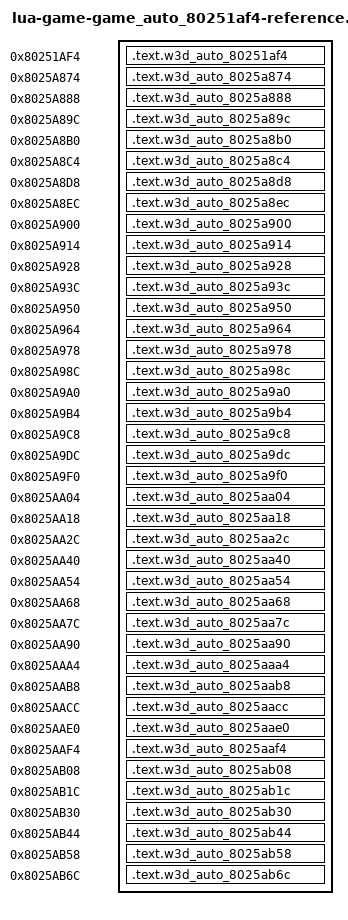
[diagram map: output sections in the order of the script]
/* Generated reference-only placements. All bodies are source-built. */
OUTPUT_FORMAT("elf32-powerpc")
OUTPUT_ARCH(powerpc)
ENTRY(w3d_auto_80251af4)
_SDA_BASE_ = 0x804b2540;
_SDA2_BASE_ = 0x804c2540;
SECTIONS {
  .text.w3d_auto_80251af4 0x80251af4 : { *(.text.w3d_auto_80251af4) }
  .text.w3d_auto_8025a874 0x8025a874 : { *(.text.w3d_auto_8025a874) }
  .text.w3d_auto_8025a888 0x8025a888 : { *(.text.w3d_auto_8025a888) }
  .text.w3d_auto_8025a89c 0x8025a89c : { *(.text.w3d_auto_8025a89c) }
  .text.w3d_auto_8025a8b0 0x8025a8b0 : { *(.text.w3d_auto_8025a8b0) }
  .text.w3d_auto_8025a8c4 0x8025a8c4 : { *(.text.w3d_auto_8025a8c4) }
  .text.w3d_auto_8025a8d8 0x8025a8d8 : { *(.text.w3d_auto_8025a8d8) }
  .text.w3d_auto_8025a8ec 0x8025a8ec : { *(.text.w3d_auto_8025a8ec) }
  .text.w3d_auto_8025a900 0x8025a900 : { *(.text.w3d_auto_8025a900) }
  .text.w3d_auto_8025a914 0x8025a914 : { *(.text.w3d_auto_8025a914) }
  .text.w3d_auto_8025a928 0x8025a928 : { *(.text.w3d_auto_8025a928) }
  .text.w3d_auto_8025a93c 0x8025a93c : { *(.text.w3d_auto_8025a93c) }
  .text.w3d_auto_8025a950 0x8025a950 : { *(.text.w3d_auto_8025a950) }
  .text.w3d_auto_8025a964 0x8025a964 : { *(.text.w3d_auto_8025a964) }
  .text.w3d_auto_8025a978 0x8025a978 : { *(.text.w3d_auto_8025a978) }
  .text.w3d_auto_8025a98c 0x8025a98c : { *(.text.w3d_auto_8025a98c) }
  .text.w3d_auto_8025a9a0 0x8025a9a0 : { *(.text.w3d_auto_8025a9a0) }
  .text.w3d_auto_8025a9b4 0x8025a9b4 : { *(.text.w3d_auto_8025a9b4) }
  .text.w3d_auto_8025a9c8 0x8025a9c8 : { *(.text.w3d_auto_8025a9c8) }
  .text.w3d_auto_8025a9dc 0x8025a9dc : { *(.text.w3d_auto_8025a9dc) }
  .text.w3d_auto_8025a9f0 0x8025a9f0 : { *(.text.w3d_auto_8025a9f0) }
  .text.w3d_auto_8025aa04 0x8025aa04 : { *(.text.w3d_auto_8025aa04) }
  .text.w3d_auto_8025aa18 0x8025aa18 : { *(.text.w3d_auto_8025aa18) }
  .text.w3d_auto_8025aa2c 0x8025aa2c : { *(.text.w3d_auto_8025aa2c) }
  .text.w3d_auto_8025aa40 0x8025aa40 : { *(.text.w3d_auto_8025aa40) }
  .text.w3d_auto_8025aa54 0x8025aa54 : { *(.text.w3d_auto_8025aa54) }
  .text.w3d_auto_8025aa68 0x8025aa68 : { *(.text.w3d_auto_8025aa68) }
  .text.w3d_auto_8025aa7c 0x8025aa7c : { *(.text.w3d_auto_8025aa7c) }
  .text.w3d_auto_8025aa90 0x8025aa90 : { *(.text.w3d_auto_8025aa90) }
  .text.w3d_auto_8025aaa4 0x8025aaa4 : { *(.text.w3d_auto_8025aaa4) }
  .text.w3d_auto_8025aab8 0x8025aab8 : { *(.text.w3d_auto_8025aab8) }
  .text.w3d_auto_8025aacc 0x8025aacc : { *(.text.w3d_auto_8025aacc) }
  .text.w3d_auto_8025aae0 0x8025aae0 : { *(.text.w3d_auto_8025aae0) }
  .text.w3d_auto_8025aaf4 0x8025aaf4 : { *(.text.w3d_auto_8025aaf4) }
  .text.w3d_auto_8025ab08 0x8025ab08 : { *(.text.w3d_auto_8025ab08) }
  .text.w3d_auto_8025ab1c 0x8025ab1c : { *(.text.w3d_auto_8025ab1c) }
  .text.w3d_auto_8025ab30 0x8025ab30 : { *(.text.w3d_auto_8025ab30) }
  .text.w3d_auto_8025ab44 0x8025ab44 : { *(.text.w3d_auto_8025ab44) }
  .text.w3d_auto_8025ab58 0x8025ab58 : { *(.text.w3d_auto_8025ab58) }
  .text.w3d_auto_8025ab6c 0x8025ab6c : { *(.text.w3d_auto_8025ab6c) }
  /DISCARD/ : { *(.text*) *(.rodata*) *(.data*) *(.bss*) *(.sdata*) *(.sbss*) *(.comment) }
}
